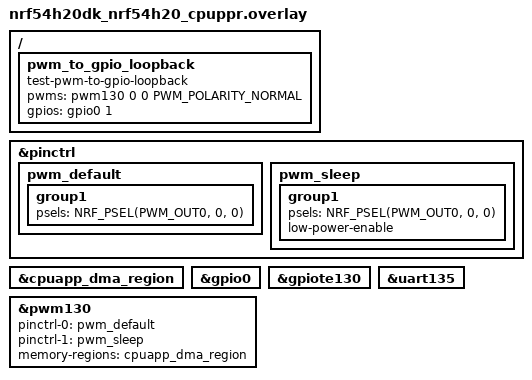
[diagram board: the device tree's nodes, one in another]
/*
 * Copyright (c) 2024 Nordic Semiconductor ASA
 *
 * SPDX-License-Identifier: LicenseRef-Nordic-5-Clause
 */

/ {
	pwm_to_gpio_loopback: pwm_to_gpio_loopback {
		compatible = "test-pwm-to-gpio-loopback";
		pwms = <&pwm130 0 0 PWM_POLARITY_NORMAL>;
		gpios = <&gpio0 1 GPIO_ACTIVE_HIGH>;
	};
};

&pinctrl {
	pwm_default: pwm_default {
		group1 {
			psels = <NRF_PSEL(PWM_OUT0, 0, 0)>;
		};
	};
	pwm_sleep: pwm_sleep {
		group1 {
			psels = <NRF_PSEL(PWM_OUT0, 0, 0)>;
			low-power-enable;
		};
	};
};

&cpuapp_dma_region {
	status = "okay";
};

&gpio0 {
	status = "okay";
};

&gpiote130 {
	status = "okay";
};

&pwm130 {
	status = "okay";
	pinctrl-0 = <&pwm_default>;
	pinctrl-1 = <&pwm_sleep>;
	pinctrl-names = "default", "sleep";
	memory-regions = <&cpuapp_dma_region>;
};

&uart135 {
	/delete-property/ hw-flow-control;
};
